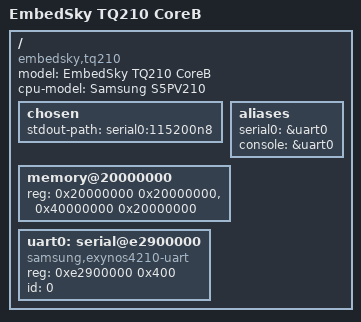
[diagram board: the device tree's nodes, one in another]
// SPDX-License-Identifier: GPL-2.0+
/dts-v1/;

/ {
	#address-cells = <1>;
	#size-cells = <1>;
	model = "EmbedSky TQ210 CoreB";
	cpu-model = "Samsung S5PV210";
	compatible = "embedsky,tq210", "samsung,s5pv210";

	chosen {
		stdout-path = "serial0:115200n8";
	};

	aliases {
		serial0 = &uart0;
		console = &uart0;
	};

	memory@20000000 {
		device_type = "memory";
		reg = <0x20000000 0x20000000>,
		      <0x40000000 0x20000000>;
	};

	uart0: serial@e2900000 {
		compatible = "samsung,exynos4210-uart";
		reg = <0xe2900000 0x400>;
		id = <0>;
		bootph-all;
		status = "okay";
	};
};
